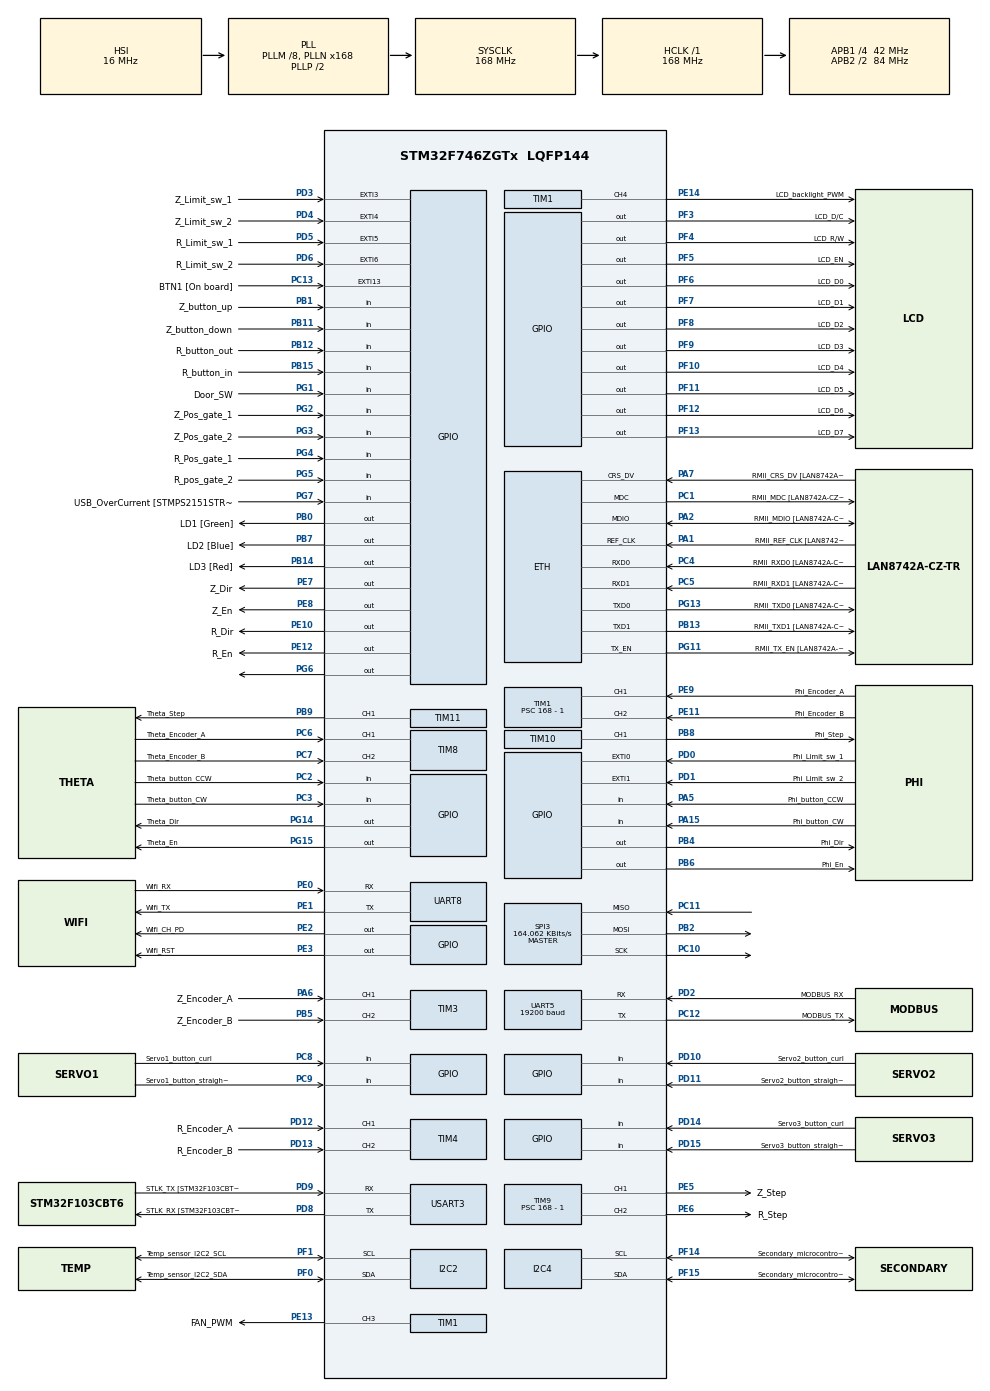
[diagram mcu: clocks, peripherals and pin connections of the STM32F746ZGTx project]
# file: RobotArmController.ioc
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ETH.MediaInterface=HAL_ETH_RMII_MODE
ETH.PHY_Name=LAN8742A_PHY_ADDRESS
ETH.PHY_Value=0
ETH.PhyAddress=0
FREERTOS.INCLUDE_pcTaskGetTaskName=1
FREERTOS.INCLUDE_xEventGroupSetBitFromISR=1
FREERTOS.INCLUDE_xTaskGetCurrentTaskHandle=1
FREERTOS.Tasks01=defaultTask,16,1024,StartDefaultTask,Default,NULL,Static,defaultTaskBuffer,defaultTaskControlBlock
FREERTOS.configCHECK_FOR_STACK_OVERFLOW=2
FREERTOS.configMAX_TASK_NAME_LEN=64
FREERTOS.configTOTAL_HEAP_SIZE=81920
FREERTOS.configUSE_NEWLIB_REENTRANT=1
I2C2.Timing=0x00A0A3F7
I2C4.Timing=0x00A0A3F7
Mcu.Family=STM32F7
Mcu.Name=STM32F746ZGTx
Mcu.Package=LQFP144
NVIC.EXTI0_IRQn=true\:5\:0\:false\:false\:true\:true\:true\:true\:true
NVIC.EXTI15_10_IRQn=true\:5\:0\:false\:false\:true\:true\:true\:true\:true
NVIC.EXTI1_IRQn=true\:5\:0\:false\:false\:true\:false\:true\:true\:true
NVIC.EXTI3_IRQn=true\:5\:0\:false\:false\:true\:false\:true\:true\:true
NVIC.EXTI4_IRQn=true\:5\:0\:false\:false\:true\:false\:true\:true\:true
NVIC.EXTI9_5_IRQn=true\:5\:0\:false\:false\:true\:false\:true\:true\:true
NVIC.PriorityGroup=NVIC_PRIORITYGROUP_4
NVIC.TIM1_BRK_TIM9_IRQn=true\:5\:0\:false\:false\:true\:true\:true\:true\:true
NVIC.TIM1_UP_TIM10_IRQn=true\:5\:0\:false\:false\:true\:true\:true\:true\:true
NVIC.TIM2_IRQn=true\:15\:0\:false\:false\:true\:false\:false\:true\:true
NVIC.TimeBase=TIM2_IRQn
NVIC.TimeBaseIP=TIM2
NVIC.UART8_IRQn=true\:5\:0\:false\:false\:true\:true\:true\:true\:true
PA0/WKUP.GPIO_Label=Servo1_PWM
PA0/WKUP.Signal=S_TIM2_CH1_ETR
PA1.GPIO_Label=RMII_REF_CLK [LAN8742A-CZ-TR_REFCLK0]
PA1.Mode=RMII
PA1.Signal=ETH_REF_CLK
PA10.GPIO_Label=USB_ID
PA10.Signal=USB_OTG_FS_ID
PA11.GPIO_Label=USB_DM
PA11.Signal=USB_OTG_FS_DM
PA12.GPIO_Label=USB_DP
PA12.Signal=USB_OTG_FS_DP
PA13.GPIO_Label=TMS
PA13.Mode=Serial_Wire
PA13.Signal=SYS_JTMS-SWDIO
PA14.GPIO_Label=TCK
PA14.Mode=Serial_Wire
PA14.Signal=SYS_JTCK-SWCLK
PA15.GPIO_Label=Phi_button_CW
PA15.GPIO_PuPd=GPIO_PULLDOWN
PA15.Signal=GPIO_Input
PA2.GPIO_Label=RMII_MDIO [LAN8742A-CZ-TR_MDIO]
PA2.Mode=RMII
PA2.Signal=ETH_MDIO
PA3.GPIO_Label=Servo2_PWM
PA3.Signal=S_TIM2_CH4
PA4.Signal=SPI3_NSS
PA5.GPIO_Label=Phi_button_CCW
PA5.GPIO_PuPd=GPIO_PULLDOWN
PA5.Signal=GPIO_Input
PA6.GPIO_Label=Z_Encoder_A
PA6.Signal=S_TIM3_CH1
PA7.GPIO_Label=RMII_CRS_DV [LAN8742A-CZ-TR_CRS_DV]
PA7.Mode=RMII
PA7.Signal=ETH_CRS_DV
PA8.GPIO_Mode=GPIO_MODE_AF_PP
PA8.GPIO_PuPd=GPIO_NOPULL
PA8.GPIO_Speed=GPIO_SPEED_FREQ_VERY_HIGH
PA8.Signal=USB_OTG_FS_SOF
PA9.GPIO_Mode=GPIO_MODE_INPUT
PA9.GPIO_PuPd=GPIO_NOPULL
PA9.Signal=USB_OTG_FS_VBUS
PB0.GPIO_Label=LD1 [Green]
PB0.Signal=GPIO_Output
PB1.GPIO_Label=Z_button_up
PB1.GPIO_PuPd=GPIO_PULLDOWN
PB1.Signal=GPIO_Input
PB10.GPIO_Label=Servo3_PWM
PB10.Signal=S_TIM2_CH3
PB11.GPIO_Label=Z_button_down
PB11.GPIO_PuPd=GPIO_PULLDOWN
PB11.Signal=GPIO_Input
PB12.GPIO_Label=R_button_out
PB12.GPIO_PuPd=GPIO_PULLDOWN
PB12.Signal=GPIO_Input
PB13.GPIO_Label=RMII_TXD1 [LAN8742A-CZ-TR_TXD1]
PB13.Mode=RMII
PB13.Signal=ETH_TXD1
PB14.GPIO_Label=LD3 [Red]
PB14.Signal=GPIO_Output
PB15.GPIO_Label=R_button_in
PB15.GPIO_PuPd=GPIO_PULLDOWN
PB15.Signal=GPIO_Input
PB2.GPIO_Mode=GPIO_MODE_AF_PP
PB2.Mode=Full_Duplex_Master
PB2.Signal=SPI3_MOSI
PB3.GPIO_Label=SW0
PB3.Signal=SYS_JTDO-SWO
PB4.GPIO_Label=Phi_Dir
PB4.Signal=GPIO_Output
PB5.GPIO_Label=Z_Encoder_B
PB5.Signal=S_TIM3_CH2
PB6.GPIO_Label=Phi_En
PB6.Signal=GPIO_Output
PB7.GPIO_Label=LD2 [Blue]
PB7.Signal=GPIO_Output
PB8.GPIO_Label=Phi_Step
PB8.Signal=S_TIM10_CH1
PB9.GPIO_Label=Theta_Step
PB9.Signal=S_TIM11_CH1
PC1.GPIO_Label=RMII_MDC [LAN8742A-CZ-TR_MDC]
PC1.Mode=RMII
PC1.Signal=ETH_MDC
PC10.Mode=Full_Duplex_Master
PC10.Signal=SPI3_SCK
PC11.Mode=Full_Duplex_Master
PC11.Signal=SPI3_MISO
PC12.GPIO_Label=MODBUS_TX
PC12.Mode=Asynchronous
PC12.Signal=UART5_TX
PC13.GPIO_Label=BTN1 [On board]
PC13.Signal=GPXTI13
PC14/OSC32_IN.Mode=LSE-External-Oscillator
PC14/OSC32_IN.Signal=RCC_OSC32_IN
PC15/OSC32_OUT.Mode=LSE-External-Oscillator
PC15/OSC32_OUT.Signal=RCC_OSC32_OUT
PC2.GPIO_Label=Theta_button_CCW
PC2.GPIO_PuPd=GPIO_PULLUP
PC2.Signal=GPIO_Input
PC3.GPIO_Label=Theta_button_CW
PC3.GPIO_PuPd=GPIO_PULLUP
PC3.Signal=GPIO_Input
PC4.GPIO_Label=RMII_RXD0 [LAN8742A-CZ-TR_RXD0]
PC4.Mode=RMII
PC4.Signal=ETH_RXD0
PC5.GPIO_Label=RMII_RXD1 [LAN8742A-CZ-TR_RXD1]
PC5.Mode=RMII
PC5.Signal=ETH_RXD1
PC6.GPIO_Label=Theta_Encoder_A
PC6.Signal=S_TIM8_CH1
PC7.GPIO_Label=Theta_Encoder_B
PC7.Signal=S_TIM8_CH2
PC8.GPIO_Label=Servo1_button_curl
PC8.GPIO_PuPd=GPIO_PULLUP
PC8.Signal=GPIO_Input
PC9.GPIO_Label=Servo1_button_straighten
PC9.GPIO_PuPd=GPIO_PULLUP
PC9.Signal=GPIO_Input
PD0.GPIO_Label=Phi_Limit_sw_1
PD0.GPIO_ModeDefaultEXTI=GPIO_MODE_IT_RISING_FALLING
PD0.GPIO_PuPd=GPIO_PULLUP
PD0.Signal=GPXTI0
PD1.GPIO_Label=Phi_Limit_sw_2
PD1.GPIO_ModeDefaultEXTI=GPIO_MODE_IT_RISING_FALLING
PD1.GPIO_PuPd=GPIO_PULLUP
PD1.Signal=GPXTI1
PD10.GPIO_Label=Servo2_button_curl
PD10.GPIO_PuPd=GPIO_PULLUP
PD10.Signal=GPIO_Input
PD11.GPIO_Label=Servo2_button_straighten
PD11.GPIO_PuPd=GPIO_PULLUP
PD11.Signal=GPIO_Input
PD12.GPIO_Label=R_Encoder_A
PD12.Signal=S_TIM4_CH1
PD13.GPIO_Label=R_Encoder_B
PD13.Signal=S_TIM4_CH2
PD14.GPIO_Label=Servo3_button_curl
PD14.GPIO_PuPd=GPIO_PULLUP
PD14.Signal=GPIO_Input
PD15.GPIO_Label=Servo3_button_straighten
PD15.GPIO_PuPd=GPIO_PULLUP
PD15.Signal=GPIO_Input
PD2.GPIO_Label=MODBUS_RX
PD2.Mode=Asynchronous
PD2.Signal=UART5_RX
PD3.GPIO_Label=Z_Limit_sw_1
PD3.GPIO_ModeDefaultEXTI=GPIO_MODE_IT_RISING_FALLING
PD3.GPIO_PuPd=GPIO_PULLUP
PD3.Signal=GPXTI3
PD4.GPIO_Label=Z_Limit_sw_2
PD4.GPIO_ModeDefaultEXTI=GPIO_MODE_IT_RISING_FALLING
PD4.GPIO_PuPd=GPIO_PULLUP
PD4.Signal=GPXTI4
PD5.GPIO_Label=R_Limit_sw_1
PD5.GPIO_ModeDefaultEXTI=GPIO_MODE_IT_RISING_FALLING
PD5.GPIO_PuPd=GPIO_PULLUP
PD5.Signal=GPXTI5
PD6.GPIO_Label=R_Limit_sw_2
PD6.GPIO_ModeDefaultEXTI=GPIO_MODE_IT_RISING_FALLING
PD6.GPIO_PuPd=GPIO_PULLUP
PD6.Signal=GPXTI6
PD8.GPIO_Label=STLK_RX [STM32F103CBT6_PA3]
PD8.Mode=Asynchronous
PD8.Signal=USART3_TX
PD9.GPIO_Label=STLK_TX [STM32F103CBT6_PA2]
PD9.Mode=Asynchronous
PD9.Signal=USART3_RX
PE0.GPIO_Label=Wifi_RX
PE0.Mode=Asynchronous
PE0.Signal=UART8_RX
PE1.GPIO_Label=Wifi_TX
PE1.Mode=Asynchronous
PE1.Signal=UART8_TX
PE10.GPIO_Label=R_Dir
PE10.Signal=GPIO_Output
PE11.GPIO_Label=Phi_Encoder_B
PE11.Signal=S_TIM1_CH2
PE12.GPIO_Label=R_En
PE12.Signal=GPIO_Output
PE13.GPIO_Label=FAN_PWM
PE13.Signal=S_TIM1_CH3
PE14.GPIO_Label=LCD_backlight_PWM
PE14.Signal=S_TIM1_CH4
PE2.GPIO_Label=Wifi_CH_PD
PE2.GPIO_Speed=GPIO_SPEED_FREQ_MEDIUM
PE2.Signal=GPIO_Output
PE3.GPIO_Label=Wifi_RST
PE3.Signal=GPIO_Output
PE5.GPIO_Label=Z_Step
PE5.Signal=S_TIM9_CH1
PE6.GPIO_Label=R_Step
PE6.Signal=S_TIM9_CH2
PE7.GPIO_Label=Z_Dir
PE7.Signal=GPIO_Output
PE8.GPIO_Label=Z_En
PE8.Signal=GPIO_Output
PE9.GPIO_Label=Phi_Encoder_A
PE9.Signal=S_TIM1_CH1
PF0.GPIO_Label=Temp_sensor_I2C2_SDA
PF0.Mode=I2C
PF0.Signal=I2C2_SDA
PF1.GPIO_Label=Temp_sensor_I2C2_SCL
PF1.Mode=I2C
PF1.Signal=I2C2_SCL
PF10.GPIO_Label=LCD_D4
PF10.GPIO_Speed=GPIO_SPEED_FREQ_HIGH
PF10.Signal=GPIO_Output
PF11.GPIO_Label=LCD_D5
PF11.GPIO_Speed=GPIO_SPEED_FREQ_HIGH
PF11.Signal=GPIO_Output
PF12.GPIO_Label=LCD_D6
PF12.GPIO_Speed=GPIO_SPEED_FREQ_HIGH
PF12.Signal=GPIO_Output
PF13.GPIO_Label=LCD_D7
PF13.GPIO_Speed=GPIO_SPEED_FREQ_HIGH
PF13.Signal=GPIO_Output
PF14.GPIO_Label=Secondary_microcontroller_I2C4_SCL
PF14.Mode=I2C
PF14.Signal=I2C4_SCL
PF15.GPIO_Label=Secondary_microcontroller_I2C4_SDA
PF15.Mode=I2C
PF15.Signal=I2C4_SDA
PF3.GPIO_Label=LCD_D/C
PF3.GPIO_PuPd=GPIO_NOPULL
PF3.GPIO_Speed=GPIO_SPEED_FREQ_HIGH
PF3.Signal=GPIO_Output
PF4.GPIO_Label=LCD_R/W
PF4.GPIO_Speed=GPIO_SPEED_FREQ_HIGH
PF4.Signal=GPIO_Output
PF5.GPIO_Label=LCD_EN
PF5.GPIO_Speed=GPIO_SPEED_FREQ_LOW
PF5.Signal=GPIO_Output
PF6.GPIO_Label=LCD_D0
PF6.GPIO_Speed=GPIO_SPEED_FREQ_HIGH
PF6.Signal=GPIO_Output
PF7.GPIO_Label=LCD_D1
PF7.GPIO_Speed=GPIO_SPEED_FREQ_HIGH
PF7.Signal=GPIO_Output
PF8.GPIO_Label=LCD_D2
PF8.GPIO_Speed=GPIO_SPEED_FREQ_HIGH
PF8.Signal=GPIO_Output
PF9.GPIO_Label=LCD_D3
PF9.GPIO_Speed=GPIO_SPEED_FREQ_HIGH
PF9.Signal=GPIO_Output
PG1.GPIO_Label=Door_SW
PG1.GPIO_PuPd=GPIO_PULLUP
PG1.Signal=GPIO_Input
PG11.GPIO_Label=RMII_TX_EN [LAN8742A-CZ-TR_TXEN]
PG11.Mode=RMII
PG11.Signal=ETH_TX_EN
PG13.GPIO_Label=RMII_TXD0 [LAN8742A-CZ-TR_TXD0]
PG13.Mode=RMII
PG13.Signal=ETH_TXD0
PG14.GPIO_Label=Theta_Dir
PG14.Signal=GPIO_Output
PG15.GPIO_Label=Theta_En
PG15.Signal=GPIO_Output
PG2.GPIO_Label=Z_Pos_gate_1
PG2.GPIO_PuPd=GPIO_PULLUP
PG2.Signal=GPIO_Input
PG3.GPIO_Label=Z_Pos_gate_2
PG3.GPIO_PuPd=GPIO_PULLUP
PG3.Signal=GPIO_Input
PG4.GPIO_Label=R_Pos_gate_1
PG4.GPIO_PuPd=GPIO_PULLUP
PG4.Signal=GPIO_Input
PG5.GPIO_Label=R_pos_gate_2
PG5.GPIO_PuPd=GPIO_PULLUP
PG5.Signal=GPIO_Input
PG6.Signal=GPIO_Output
PG7.GPIO_Label=USB_OverCurrent [STMPS2151STR_FAULT]
PG7.Signal=GPIO_Input
PH0/OSC_IN.GPIO_Label=MCO [STM32F103CBT6_PA8]
PH0/OSC_IN.Signal=RCC_OSC_IN
PH1/OSC_OUT.Signal=RCC_OSC_OUT
ProjectManager.HeapSize=0x200
ProjectManager.StackSize=0x400
ProjectManager.TargetToolchain=STM32CubeIDE
RCC.48MHZClocksFreq_Value=24000000
RCC.AHBFreq_Value=168000000
RCC.APB1CLKDivider=RCC_HCLK_DIV4
RCC.APB1Freq_Value=42000000
RCC.APB1TimFreq_Value=84000000
RCC.APB2CLKDivider=RCC_HCLK_DIV2
RCC.APB2Freq_Value=84000000
RCC.APB2TimFreq_Value=168000000
RCC.CortexFreq_Value=168000000
RCC.HCLKFreq_Value=168000000
RCC.HSE_VALUE=8000000
RCC.HSI_VALUE=16000000
RCC.PLLM=8
RCC.PLLMUL=RCC_PLL_MUL9
RCC.PLLN=168
RCC.PLLQ=7
RCC.PRESCALERUSB=RCC_USBCLKSOURCE_PLL_DIV1_5
RCC.SYSCLKFreq_VALUE=168000000
RCC.SYSCLKSource=RCC_SYSCLKSOURCE_PLLCLK
RCC.SYSCLKSourceVirtual=RCC_SYSCLKSOURCE_PLLCLK
RCC.USBFreq_Value=48000000
RCC.VCOOutputFreq_Value=336000000
SH.S_TIM10_CH1.0=TIM10_CH1,PWM Generation1 CH1
SH.S_TIM11_CH1.0=TIM11_CH1,PWM Generation1 CH1
SH.S_TIM1_CH1.0=TIM1_CH1,Encoder_Interface
SH.S_TIM1_CH2.0=TIM1_CH2,Encoder_Interface
SH.S_TIM1_CH3.0=TIM1_CH3,PWM Generation3 CH3
SH.S_TIM1_CH4.0=TIM1_CH4,PWM Generation4 CH4
SH.S_TIM2_CH1_ETR.0=TIM2_CH1
SH.S_TIM2_CH3.0=TIM2_CH3
SH.S_TIM2_CH4.0=TIM2_CH4
SH.S_TIM3_CH1.0=TIM3_CH1,Encoder_Interface
SH.S_TIM3_CH2.0=TIM3_CH2,Encoder_Interface
SH.S_TIM4_CH1.0=TIM4_CH1,Encoder_Interface
SH.S_TIM4_CH2.0=TIM4_CH2,Encoder_Interface
SH.S_TIM8_CH1.0=TIM8_CH1,Encoder_Interface
SH.S_TIM8_CH2.0=TIM8_CH2,Encoder_Interface
SH.S_TIM9_CH1.0=TIM9_CH1,PWM Generation1 CH1
SH.S_TIM9_CH2.0=TIM9_CH2,PWM Generation2 CH2
SPI3.BaudRatePrescaler=SPI_BAUDRATEPRESCALER_256
SPI3.CLKPhase=SPI_PHASE_2EDGE
SPI3.CLKPolarity=SPI_POLARITY_HIGH
SPI3.CRCCalculation=SPI_CRCCALCULATION_DISABLE
SPI3.CalculateBaudRate=164.062 KBits/s
SPI3.DataSize=SPI_DATASIZE_8BIT
SPI3.Direction=SPI_DIRECTION_2LINES
SPI3.FirstBit=SPI_FIRSTBIT_LSB
SPI3.Mode=SPI_MODE_MASTER
SPI3.VirtualType=VM_MASTER
TIM1.Channel-PWM\ Generation3\ CH3=TIM_CHANNEL_3
TIM1.Channel-PWM\ Generation4\ CH4=TIM_CHANNEL_4
TIM1.Period=1000 - 1
TIM1.Prescaler=168 - 1
TIM10.Channel=TIM_CHANNEL_1
TIM10.Period=1000 - 1
TIM10.Prescaler=168 - 1
TIM10.Pulse=499
TIM11.Channel=TIM_CHANNEL_1
TIM9.Channel-PWM\ Generation1\ CH1=TIM_CHANNEL_1
TIM9.Channel-PWM\ Generation2\ CH2=TIM_CHANNEL_2
TIM9.Period=1500 - 1
TIM9.Prescaler=168 - 1
TIM9.Pulse-PWM\ Generation1\ CH1=499
TIM9.Pulse-PWM\ Generation2\ CH2=499
UART5.BaudRate=19200
UART5.Parity=PARITY_EVEN
UART8.SwapParam=UART_ADVFEATURE_SWAP_ENABLE
USART3.VirtualMode-Asynchronous=VM_ASYNC
VP_FREERTOS_VS_CMSIS_V2.Mode=CMSIS_V2
VP_SYS_VS_tim2.Mode=TIM2
VP_TIM10_VS_ClockSourceINT.Mode=Enable_Timer
VP_TIM11_VS_ClockSourceINT.Mode=Enable_Timer
VP_TIM9_VS_ClockSourceINT.Mode=Internal
board=NUCLEO-F746ZG

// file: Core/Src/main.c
/* USER CODE BEGIN Header */
/**
  ******************************************************************************
  * @file           : main.c
  * @brief          : Main program body
  ******************************************************************************
  * @attention
  *
  * Copyright (c) 2024 STMicroelectronics.
  * All rights reserved.
  *
  * This software is licensed under terms that can be found in the LICENSE file
  * in the root directory of this software component.
  * If no LICENSE file comes with this software, it is provided AS-IS.
  *
  ******************************************************************************
  */
/* USER CODE END Header */
#include "main.h"
#include "cmsis_os.h"
#include "eth.h"
#include "i2c.h"
#include "spi.h"
#include "tim.h"
#include "usart.h"
#include "gpio.h"

/* USER CODE BEGIN Includes */
#include "cJSON/cJSON.h"

#include "limitswitch.h"
#include "logger.h"
#include "stepper_motor.h"
#include "retarget_io.h"
#include "wifi_module.h"
/* USER CODE END Includes */

void SystemClock_Config(void);
void MX_FREERTOS_Init(void);

int main(void)
{

  /* MCU Configuration--------------------------------------------------------*/

  /* Reset of all peripherals, Initializes the Flash interface and the Systick. */
  HAL_Init();

  /* Configure the system clock */
  SystemClock_Config();

  /* Initialize all configured peripherals */
  MX_GPIO_Init();
  MX_ETH_Init();
  MX_USART3_UART_Init();
  MX_I2C2_Init();
  MX_SPI3_Init();
  MX_TIM1_Init();
  MX_TIM3_Init();
  MX_TIM4_Init();
  MX_TIM8_Init();
  MX_TIM9_Init();
  MX_TIM10_Init();
  MX_TIM11_Init();
  MX_UART5_Init();
  MX_UART8_Init();
  MX_I2C4_Init();
  /* USER CODE BEGIN 2 */
    initLimitswitches();
    initStepperMotors();
    initWifiModule();
    // Set SPI3 NSS signal to idle
    HAL_GPIO_WritePin(GPIOA, GPIO_PIN_4, GPIO_PIN_SET);

    initRetargetIo();
    Logger_Init(200);

    // Use FreeRTOS memory management for cJSON
    cJSON_Hooks hooks;
    hooks.malloc_fn = pvPortMalloc;
    hooks.free_fn = vPortFree;
    cJSON_InitHooks(&hooks);

    HAL_GPIO_WritePin(LD3_GPIO_Port, LD3_Pin, GPIO_PIN_RESET);
  /* USER CODE END 2 */

  /* Init scheduler */
  osKernelInitialize();

  /* Call init function for freertos objects (in cmsis_os2.c) */
  MX_FREERTOS_Init();

  /* Start scheduler */
  osKernelStart();

  /* We should never get here as control is now taken by the scheduler */

  /* Infinite loop */
  while (1)
  {

  }
}

void SystemClock_Config(void)
{
  RCC_OscInitTypeDef RCC_OscInitStruct = {0};
  RCC_ClkInitTypeDef RCC_ClkInitStruct = {0};

  /** Configure LSE Drive Capability
  */
  HAL_PWR_EnableBkUpAccess();

  /** Configure the main internal regulator output voltage
  */
  __HAL_RCC_PWR_CLK_ENABLE();
  __HAL_PWR_VOLTAGESCALING_CONFIG(PWR_REGULATOR_VOLTAGE_SCALE2);

  /** Initializes the RCC Oscillators according to the specified parameters
  * in the RCC_OscInitTypeDef structure.
  */
  RCC_OscInitStruct.OscillatorType = RCC_OSCILLATORTYPE_HSI;
  RCC_OscInitStruct.HSIState = RCC_HSI_ON;
  RCC_OscInitStruct.HSICalibrationValue = RCC_HSICALIBRATION_DEFAULT;
  RCC_OscInitStruct.PLL.PLLState = RCC_PLL_ON;
  RCC_OscInitStruct.PLL.PLLSource = RCC_PLLSOURCE_HSI;
  RCC_OscInitStruct.PLL.PLLM = 8;
  RCC_OscInitStruct.PLL.PLLN = 168;
  RCC_OscInitStruct.PLL.PLLP = RCC_PLLP_DIV2;
  RCC_OscInitStruct.PLL.PLLQ = 7;
  if (HAL_RCC_OscConfig(&RCC_OscInitStruct) != HAL_OK)
  {
    Error_Handler();
  }

  /** Initializes the CPU, AHB and APB buses clocks
  */
  RCC_ClkInitStruct.ClockType = RCC_CLOCKTYPE_HCLK|RCC_CLOCKTYPE_SYSCLK
                              |RCC_CLOCKTYPE_PCLK1|RCC_CLOCKTYPE_PCLK2;
  RCC_ClkInitStruct.SYSCLKSource = RCC_SYSCLKSOURCE_PLLCLK;
  RCC_ClkInitStruct.AHBCLKDivider = RCC_SYSCLK_DIV1;
  RCC_ClkInitStruct.APB1CLKDivider = RCC_HCLK_DIV4;
  RCC_ClkInitStruct.APB2CLKDivider = RCC_HCLK_DIV2;

  if (HAL_RCC_ClockConfig(&RCC_ClkInitStruct, FLASH_LATENCY_5) != HAL_OK)
  {
    Error_Handler();
  }
}

void HAL_TIM_PeriodElapsedCallback(TIM_HandleTypeDef *htim)
{
  if (htim->Instance == TIM2)
  {
    HAL_IncTick();
  }
}

void Error_Handler(void)
{
  /* USER CODE BEGIN Error_Handler_Debug */
  /* User can add his own implementation to report the HAL error return state */
    HAL_GPIO_WritePin(LD3_GPIO_Port, LD3_Pin, GPIO_PIN_SET);
  __disable_irq();
  while (1)
  {
  }
  /* USER CODE END Error_Handler_Debug */
}

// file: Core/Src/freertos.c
/* USER CODE BEGIN Header */
/**
  ******************************************************************************
  * File Name          : freertos.c
  * Description        : Code for freertos applications
  ******************************************************************************
  * @attention
  *
  * Copyright (c) 2024 STMicroelectronics.
  * All rights reserved.
  *
  * This software is licensed under terms that can be found in the LICENSE file
  * in the root directory of this software component.
  * If no LICENSE file comes with this software, it is provided AS-IS.
  *
  ******************************************************************************
  */
/* USER CODE END Header */

#include "FreeRTOS.h"
#include "task.h"
#include "main.h"
#include "cmsis_os.h"

/* USER CODE BEGIN Includes */

#include <stdbool.h>
#include <stdint.h>
#include <stdio.h>
#include <string.h>

#include "event_groups.h"
#include "queue.h"
#include "semphr.h"

#include "limitswitch.h"
#include "logger.h"
#include "mechanical_conf.h"
#include "rtos_priorities.h"
#include "stepper_motor.h"
#include "tim.h"
#include "translation.h" // TODO: Solve naming conflicts.
#include "usart.h"
#include "spi.h"

#include "KAR_MC_handler.h"
#include "WifiController/WifiController.h"
#include "WifiController/SerialHelper.h"

/* USER CODE END Includes */

typedef StaticTask_t osStaticThreadDef_t;
/* USER CODE BEGIN PTD */

typedef int32_t MC_Step_t;

typedef struct PositionCylindrical
{
    MC_Step_t r;
    MC_Step_t phi;
    MC_Step_t z;
} PositionCylindrical_t;

typedef enum AppState
{
    AppState_Error,
    AppState_Idle,
    AppState_DemoMoveControl,
    AppState_GpioControl,
    AppState_WifiControl,
	AppState_ps2Control
} AppState_t;

/* USER CODE END PTD */

/* USER CODE BEGIN PD */

// Task settings
#define INDICATOR_BLINKING_TASK_STACK_SIZE 512
#define INDICATOR_BLINKING_TASK_PRIORITY TASK_PRIORITY_LOWEST
#define WIFI_RECEIVE_TASK_STACK_SIZE 2048
#define WIFI_RECEIVE_TASK_PRIORITY TASK_PRIORITY_ABOVE_NORMAL
#define DEMO_MOVE_CONTROL_TASK_STACK_SIZE 1024
#define DEMO_MOVE_CONTROL_TASK_PRIORITY TASK_PRIORITY_NORMAL
#define GPIO_CONTROL_TASK_STACK_SIZE 1024
#define GPIO_CONTROL_TASK_PRIORITY TASK_PRIORITY_NORMAL
#define PS2_CONTROL_TASK_STACK_SIZE 1024
#define PS2_CONTROL_TASK_PRIORITY TASK_PRIORITY_NORMAL
#define WIFI_CONTROL_TASK_STACK_SIZE 1024
#define WIFI_CONTROL_TASK_PRIORITY TASK_PRIORITY_NORMAL
#define SETUP_TASK_STACK_SIZE 1024
#define SETUP_TASK_PRIORITY TASK_PRIORITY_NORMAL

// Queue settings
#define NEXT_POSITION_QUEUE_LENGTH 64
#define NEXT_POSITION_QUEUE_ITEM_SIZE sizeof(PositionCylindrical_t)

// Event group settings
#define STATE_DEMO_MOVE_CONTROL_BIT (1 << 0)
#define STATE_GPIO_CONTROL_BIT (1 << 1)
#define STATE_WIFI_CONTROL_BIT (1 << 2)
#define STATE_PS2_CONTROL_BIT (1 << 3)

/* USER CODE END PD */

/* USER CODE BEGIN Variables */

// Task variables
static StaticTask_t demoMoveControlTaskBuffer;
static StackType_t demoMoveControlTaskStack[DEMO_MOVE_CONTROL_TASK_STACK_SIZE];
TaskHandle_t demoMoveControlTaskHandle = NULL;
static StaticTask_t gpioControlTaskBuffer;
static StackType_t gpioControlTaskStack[GPIO_CONTROL_TASK_STACK_SIZE];
TaskHandle_t gpioControlTaskHandle = NULL;
static StaticTask_t ps2ControlTaskBuffer;
static StackType_t ps2ControlTaskStack[PS2_CONTROL_TASK_STACK_SIZE];
TaskHandle_t ps2ControlTaskHandle = NULL;
static StaticTask_t indicatorBlinkingTaskBuffer;
static StackType_t indicatorBlinkingTaskStack[INDICATOR_BLINKING_TASK_STACK_SIZE];
TaskHandle_t indicatorBlinkingTaskHandle = NULL;
TaskHandle_t setupTaskHandle = NULL;
static StaticTask_t wifiControlTaskBuffer;
static StackType_t wifiControlTaskStack[WIFI_CONTROL_TASK_STACK_SIZE];
TaskHandle_t wifiControlTaskHandle = NULL;
static StaticTask_t wifiReceiveTaskBuffer;
static StackType_t wifiReceiveTaskStack[WIFI_RECEIVE_TASK_STACK_SIZE];
TaskHandle_t wifiReceiveTaskHandle = NULL;

// Semaphores and mutexes
StaticSemaphore_t controlMutexBuffer;
SemaphoreHandle_t controlMutexHandle = NULL;
StaticSemaphore_t wifiReceiveStartedFlagBuffer;
SemaphoreHandle_t wifiReceiveStartedFlagHandle = NULL;

// Queue variables
static StaticQueue_t nextPositionQueueBuffer;
static uint8_t nextPositionQueueStorageArea[NEXT_POSITION_QUEUE_LENGTH * NEXT_POSITION_QUEUE_ITEM_SIZE];
QueueHandle_t nextPositionQueueHandle = NULL;

// Event group variables
static StaticEventGroup_t stateEventGroupBuffer;
EventGroupHandle_t stateEventGroupHandle = NULL;

// Other variables
volatile AppState_t appState = AppState_Idle;

/* USER CODE END Variables */
/* Definitions for defaultTask */
osThreadId_t defaultTaskHandle;
uint32_t defaultTaskBuffer[ 1024 ];
osStaticThreadDef_t defaultTaskControlBlock;
const osThreadAttr_t defaultTask_attributes = {
  .name = "defaultTask",
  .cb_mem = &defaultTaskControlBlock,
  .cb_size = sizeof(defaultTaskControlBlock),
  .stack_mem = &defaultTaskBuffer[0],
  .stack_size = sizeof(defaultTaskBuffer),
  .priority = (osPriority_t) osPriorityBelowNormal,
};

/* USER CODE BEGIN FunctionPrototypes */

// Task functions
void demoMoveControlTask(void *pvParameters);
void gpioControlTask(void *pvParameters);
void ps2ControlTask(void *pvParameters);
void indicatorBlinkingTask(void *pvParameters);
void setupTask(void *pvParameters);
void wifiControlTask(void *pvParameters);
void wifiReceiveTask(void *pvParameters);

static void changeAppStateFromISR(BaseType_t *xHigherPriorityTaskWoken);
static bool debounce(uint32_t *last_tick, uint32_t tick_count);
static void handleButtonAction(const char *args);
static void homingSequence();
static void moveToPosition(const PositionCylindrical_t *position);
static void sendNewPosition(const char *btn);
static void setupWifi();

/* USER CODE END FunctionPrototypes */

void StartDefaultTask(void *argument);

void MX_FREERTOS_Init(void); /* (MISRA C 2004 rule 8.1) */

/* Hook prototypes */
void vApplicationStackOverflowHook(xTaskHandle xTask, signed char *pcTaskName);

/* USER CODE BEGIN 4 */
void vApplicationStackOverflowHook(xTaskHandle xTask, signed char *pcTaskName)
{
   /* Run time stack overflow checking is performed if
   configCHECK_FOR_STACK_OVERFLOW is defined to 1 or 2. This hook function is
   called if a stack overflow is detected. */
    printf("Stack Overflow: %s\n", pcTaskName);
    while (1)
    {
    }
}
/* USER CODE END 4 */

void MX_FREERTOS_Init(void) {

  /* USER CODE BEGIN RTOS_MUTEX */
    controlMutexHandle = xSemaphoreCreateMutexStatic(&controlMutexBuffer);
    wifiReceiveStartedFlagHandle = xSemaphoreCreateBinaryStatic(&wifiReceiveStartedFlagBuffer);
  /* USER CODE END RTOS_MUTEX */

  /* USER CODE BEGIN RTOS_QUEUES */
    nextPositionQueueHandle = xQueueCreateStatic(
        NEXT_POSITION_QUEUE_LENGTH,
        NEXT_POSITION_QUEUE_ITEM_SIZE,
        nextPositionQueueStorageArea,
        &nextPositionQueueBuffer);
    configASSERT(nextPositionQueueHandle != NULL);
  /* USER CODE END RTOS_QUEUES */

  /* Create the thread(s) */
  /* creation of defaultTask */
  defaultTaskHandle = osThreadNew(StartDefaultTask, NULL, &defaultTask_attributes);

  /* USER CODE BEGIN RTOS_THREADS */
    indicatorBlinkingTaskHandle = xTaskCreateStatic(
          indicatorBlinkingTask,
          "IndicatorBlinking",
          INDICATOR_BLINKING_TASK_STACK_SIZE,
          NULL,
          INDICATOR_BLINKING_TASK_PRIORITY,
          indicatorBlinkingTaskStack,
          &indicatorBlinkingTaskBuffer);
    configASSERT(indicatorBlinkingTaskHandle != NULL);

    wifiReceiveTaskHandle = xTaskCreateStatic(
          wifiReceiveTask,
          "WifiReceive",
          WIFI_RECEIVE_TASK_STACK_SIZE,
          NULL,
          WIFI_RECEIVE_TASK_PRIORITY,
          wifiReceiveTaskStack,
          &wifiReceiveTaskBuffer);
    configASSERT(wifiReceiveTaskHandle != NULL);

    demoMoveControlTaskHandle = xTaskCreateStatic(
          demoMoveControlTask,
          "DemoMoveControl",
          DEMO_MOVE_CONTROL_TASK_STACK_SIZE,
          NULL,
          DEMO_MOVE_CONTROL_TASK_PRIORITY,
          demoMoveControlTaskStack,
          &demoMoveControlTaskBuffer);
    configASSERT(demoMoveControlTaskHandle != NULL);

    gpioControlTaskHandle = xTaskCreateStatic(
          gpioControlTask,
          "GpioControl",
          GPIO_CONTROL_TASK_STACK_SIZE,
          NULL,
          GPIO_CONTROL_TASK_PRIORITY,
          gpioControlTaskStack,
          &gpioControlTaskBuffer);
    configASSERT(gpioControlTaskHandle != NULL);

    ps2ControlTaskHandle = xTaskCreateStatic(
          ps2ControlTask,
          "ps2Control",
          PS2_CONTROL_TASK_STACK_SIZE,
          NULL,
          PS2_CONTROL_TASK_PRIORITY,
          ps2ControlTaskStack,
          &ps2ControlTaskBuffer);
    configASSERT(ps2ControlTaskHandle != NULL);

    wifiControlTaskHandle = xTaskCreateStatic(
          wifiControlTask,
          "WifiControl",
          WIFI_CONTROL_TASK_STACK_SIZE,
          NULL,
          WIFI_CONTROL_TASK_PRIORITY,
          wifiControlTaskStack,
          &wifiControlTaskBuffer);
    configASSERT(wifiControlTaskHandle != NULL);

    configASSERT(xTaskCreate(
          setupTask,
          "Setup",
          SETUP_TASK_STACK_SIZE,
          NULL,
          SETUP_TASK_PRIORITY,
          &setupTaskHandle) == pdPASS);
  /* USER CODE END RTOS_THREADS */

  /* USER CODE BEGIN RTOS_EVENTS */
    stateEventGroupHandle = xEventGroupCreateStatic(&stateEventGroupBuffer);
    configASSERT(stateEventGroupHandle != NULL);
  /* USER CODE END RTOS_EVENTS */

}

void StartDefaultTask(void *argument)
{
  /* USER CODE BEGIN StartDefaultTask */
    while (1)
    {
        PositionCylindrical_t cp = { -1, -1, -1 };
        vPortEnterCritical();
        cp.r = stepper_motors[MC_MOTORID_R].currPos;
        cp.phi = stepper_motors[MC_MOTORID_PHI].currPos;
        cp.z = stepper_motors[MC_MOTORID_Z].currPos;
        vPortExitCritical();
        logInfo(
            "position: (%ld, %ld, %ld), state: %d",
            cp.r, cp.phi, cp.z,
            appState);

        size_t free_heap_size = xPortGetFreeHeapSize();
        size_t minimum_free_heap_size = xPortGetMinimumEverFreeHeapSize();
        logInfo(
            "heap\n"
            "\t- free heap: %ul / %ul (%d %%)\n"
            "\t- minimum free heap: %ul / %ul (%d %%)",
            free_heap_size,
            configTOTAL_HEAP_SIZE,
            100 * free_heap_size / configTOTAL_HEAP_SIZE,
            minimum_free_heap_size,
            configTOTAL_HEAP_SIZE,
            100 * minimum_free_heap_size / configTOTAL_HEAP_SIZE);

        vTaskDelay(pdMS_TO_TICKS(3000));
    }
  /* USER CODE END StartDefaultTask */
}

/* USER CODE BEGIN Application */

/*
 *===================================================================*
 * Function name: homing_sequence
 *-------------------------------------------------------------------
 * Description:
 * This function is responsible the to do the first homing sequence. It drives all the motors towards negative direction
 * to the point where all of the axis are at the zero position. Here the current position values get the zero initial value.
 * After the sequence the timer interrupts can follow the movement of the arm.
 * After power reset homing must run again.
 *-------------------------------------------------------------------
 */
static void homingSequence()
{
    e_MC_ErrorCode_t ec = u8_MC_StartAllMotor_f(stepper_motors, MC_DIR_NEGATIVE);

    if (ec == e_MC_ErrorCode_OK)
    {
        bool r_finished = false, phi_finished = false, z_finished = false;

        // Waiting until all of the motors have reached their limit
        while (!(r_finished && phi_finished && z_finished))
        {
            // R axis check
            if ((!r_finished) && limit_switches[MC_MOTORID_R].null_point)
            {
                v_MC_StopMotor_f(stepper_motors, MC_MOTORID_R);
                stepper_motors[MC_MOTORID_R].currPos = 0;
                r_finished = true;
            }

            // Phi axis check
            if ((!phi_finished) && limit_switches[MC_MOTORID_PHI].null_point)
            {
                v_MC_StopMotor_f(stepper_motors, MC_MOTORID_PHI);
                stepper_motors[MC_MOTORID_PHI].currPos = 0;
                phi_finished = true;
            }

            // Z axis check
            if ((!z_finished) && limit_switches[MC_MOTORID_Z].null_point)
            {
                v_MC_StopMotor_f(stepper_motors, MC_MOTORID_Z);
                stepper_motors[MC_MOTORID_Z].currPos = 0;
                z_finished = true;
            }

            vTaskDelay(10);
        }

        logInfo("Homing complete.");
    }
    else
    {
        logError("Homig error!");
        Error_Handler();
    }
}

static void changeAppStateFromISR(BaseType_t *pxHigherPriorityTaskWoken)
{
    // Change the app state and wake up the appropriate task.
    switch (appState)
    {
    case AppState_Idle:
        appState = AppState_DemoMoveControl;
        xEventGroupSetBitsFromISR(
                stateEventGroupHandle,
                STATE_DEMO_MOVE_CONTROL_BIT,
                pxHigherPriorityTaskWoken);
        break;
    case AppState_DemoMoveControl:
        appState = AppState_GpioControl;
        xEventGroupSetBitsFromISR(
                stateEventGroupHandle,
                STATE_GPIO_CONTROL_BIT,
                pxHigherPriorityTaskWoken);
        break;
    case AppState_GpioControl:
        appState = AppState_WifiControl;
        xEventGroupSetBitsFromISR(
                stateEventGroupHandle,
                STATE_WIFI_CONTROL_BIT,
                pxHigherPriorityTaskWoken);
        break;
    case AppState_WifiControl:
        appState = AppState_ps2Control;
        xEventGroupSetBitsFromISR(
                stateEventGroupHandle,
                STATE_PS2_CONTROL_BIT,
                pxHigherPriorityTaskWoken);
        break;
    case AppState_ps2Control:
        appState = AppState_DemoMoveControl;
        xEventGroupSetBitsFromISR(
                stateEventGroupHandle,
                STATE_DEMO_MOVE_CONTROL_BIT,
                pxHigherPriorityTaskWoken);
        break;
    default:
        appState = AppState_Error;
        break;
    }
}

static bool debounce(uint32_t *last_tick, uint32_t tick_count)
{
    uint32_t current_tick = HAL_GetTick();
    if (current_tick - *last_tick > tick_count)
    {
        *last_tick = current_tick;
        return true;
    }
    return false;
}

static inline bool check_move_finished(const s_MC_StepperMotor *sm, const s_GEO_LimitSwitch *ls)
{
    // {next position reached} || {limit max reached} || {limit min reached}
    return ((sm->dir == MC_DIR_POSITIVE) ? (sm->currPos >= sm->nextPos) : (sm->currPos <= sm->nextPos))
            || (ls->max_point && (sm->dir == MC_DIR_POSITIVE))
            || (ls->null_point && (sm->dir == MC_DIR_NEGATIVE));
}

static void moveToPosition(const PositionCylindrical_t *position)
{
    vPortEnterCritical();
    stepper_motors[MC_MOTORID_R].nextPos = position->r;
    stepper_motors[MC_MOTORID_PHI].nextPos = position->phi;
    stepper_motors[MC_MOTORID_Z].nextPos = position->z;
    vPortExitCritical();

    u8_MC_setAllMotorDir_TowardsDesiredPos_f(stepper_motors);

    u8_MC_StartMotor_f(stepper_motors, MC_MOTORID_R, stepper_motors[MC_MOTORID_R].dir);
    u8_MC_StartMotor_f(stepper_motors, MC_MOTORID_PHI, stepper_motors[MC_MOTORID_PHI].dir);
    u8_MC_StartMotor_f(stepper_motors, MC_MOTORID_Z, stepper_motors[MC_MOTORID_Z].dir);

    bool r_finished = false;
    bool phi_finished = false;
    bool z_finished = false;

    /* Wait for tool to reach next position */
    while (!(r_finished && phi_finished && z_finished))
    {
        if ((!r_finished) && check_move_finished(&(stepper_motors[MC_MOTORID_R]), &(limit_switches[MC_MOTORID_R])))
        {
            v_MC_StopMotor_f(stepper_motors, MC_MOTORID_R);
            r_finished = true;
        }

        if ((!phi_finished) && check_move_finished(&(stepper_motors[MC_MOTORID_PHI]), &(limit_switches[MC_MOTORID_PHI])))
        {
            v_MC_StopMotor_f(stepper_motors, MC_MOTORID_PHI);
            phi_finished = true;
        }

        if ((!z_finished) && check_move_finished(&(stepper_motors[MC_MOTORID_Z]), &(limit_switches[MC_MOTORID_Z])))
        {
            v_MC_StopMotor_f(stepper_motors, MC_MOTORID_Z);
            z_finished = true;
        }

        vTaskDelay(pdMS_TO_TICKS(10));
    }
}

static void sendNewPosition(const char *btn)
{
    PositionCylindrical_t position;
    // Disable OS and interrupts while creating local copy of global data.
    vPortEnterCritical();
    position.r = stepper_motors[MC_MOTORID_R].currPos;
    position.phi = stepper_motors[MC_MOTORID_PHI].currPos;
    position.z = stepper_motors[MC_MOTORID_Z].currPos;
    vPortExitCritical();

    // The press of a button moves the robot 1/20 of the full range along the specific axis.
    const MC_Step_t inc_r = MC_MAXPOS_R / 20;
    const MC_Step_t inc_phi = MC_MAXPOS_PHI / 20;
    const MC_Step_t inc_z = MC_MAXPOS_Z / 20;

    if (strncmp(btn, "rp", 2) == 0)
    {
        position.r += inc_r;
        if (position.r > MC_MAXPOS_R)
        {
            position.r = MC_MAXPOS_R;
        }
    }
    else if (strncmp(btn, "rm", 2) == 0)
    {
        position.r -= inc_r;
        if (position.r < 0)
        {
            position.r = 0;
        }
    }
    else if (strncmp(btn, "fp", 2) == 0)
    {
        position.phi += inc_phi;
        if (position.phi > MC_MAXPOS_PHI)
        {
            position.phi = MC_MAXPOS_PHI;
        }
    }
    else if (strncmp(btn, "fm", 2) == 0)
    {
        position.phi -= inc_phi;
        if (position.phi < 0)
        {
            position.phi = 0;
        }
    }
    else if (strncmp(btn, "zp", 2) == 0)
    {
        position.z += inc_z;
        if (position.z > MC_MAXPOS_Z)
        {
            position.z = MC_MAXPOS_Z;
        }
    }
    else if (strncmp(btn, "zm", 2) == 0)
    {
        position.z -= inc_z;
        if (position.z < 0)
        {
            position.z = 0;
        }
    }
    else if (strncmp(btn, "hx", 2) == 0)
    {
        position.r = 0;
        position.phi = 0;
        position.z = 0;
    }

    xQueueSend(nextPositionQueueHandle, &position, 10);
}

static void handleButtonAction(const char *args)
{
    // Use the default GUI of the Wi-Fi controller which provides simple buttons for moving the
    // motors of the robotarm.
    char btn[3] = { '\0' };

    const char *arg_text = "btn=";
    const size_t arg_text_length = 4;

    char *p = strstr(args, arg_text);
    if ((p != NULL) && (strlen(p) >= (arg_text_length + 2)))
    {
        strncpy(btn, p + arg_text_length, 2);
        sendNewPosition(btn);
    }
    else
    {
        strcpy(btn, "xx");
    }

    logInfo("Button action: %s", btn);
}

const char *find_param_value(const char *message, const char *param_name)
{
    // TODO: This is just an arbitrary number. Further investigation needed!
    #define MAX_PARAM_NAME_LENGTH 32

    char pattern[MAX_PARAM_NAME_LENGTH + 2] = {'\0'};
    snprintf(pattern, MAX_PARAM_NAME_LENGTH + 2, "%s=", param_name);
    char *start = strstr(message, pattern);
    if (!start)
    {
        return NULL;
    }
    return start + strlen(pattern);
}

static void handleCoordCylAction(const char *args)
{
    const char *param_r = "r";
    const char *param_phi = "phi";
    const char *param_z = "z";

    PositionCylindrical_t position;
    const char *param_value_ptr = NULL;
    int param_value = 0;

    param_value_ptr = find_param_value(args, param_r);
    if (param_value_ptr != NULL)
    {
        sscanf(param_value_ptr, "%d", &param_value);
        position.r = (param_value <= 0) ? 0 : (param_value > MOTOR_TOTAL_STEP_R) ? MOTOR_TOTAL_STEP_R : param_value;
    }
    else
    {
        position.r = param_value = 0;
    }

    param_value_ptr = find_param_value(args, param_phi);
    if (param_value_ptr != NULL)
    {
        sscanf(param_value_ptr, "%d", &param_value);
        position.phi = (param_value <= 0) ? 0 : (param_value > MOTOR_TOTAL_STEP_PHI) ? MOTOR_TOTAL_STEP_PHI : param_value;
    }
    else
    {
        position.phi = param_value = 0;
    }

    param_value_ptr = find_param_value(args, param_z);
    if (param_value_ptr != NULL)
    {
        sscanf(param_value_ptr, "%d", &param_value);
        position.z = (param_value <= 0) ? 0 : (param_value > MOTOR_TOTAL_STEP_Z) ? MOTOR_TOTAL_STEP_Z : param_value;
    }
    else
    {
        position.z = param_value = 0;
    }

    logInfo("Leap: (%ld, %ld, %ld)", position.r, position.phi, position.z);

    xQueueSend(nextPositionQueueHandle, &position, 10);
}

static void setupWifi()
{
    const char *ap_ssid = "indactrobot";
    const char *ap_password = "pirosalma";

    WifiController_ActionList_t *action_list = WifiController_WifiController_GetActionList();
    WifiController_ActionList_Add(action_list, "/button", handleButtonAction);
    WifiController_ActionList_Add(action_list, "/coord/cyl", handleCoordCylAction);

    int count = 0;
    while ((uxSemaphoreGetCount(wifiReceiveStartedFlagHandle) == 0)
            && (count < 100))
    {
        count++;
        vTaskDelay(10);
    }
    if (uxSemaphoreGetCount(wifiReceiveStartedFlagHandle) == 0)
    {
        logError("WifiReceive task was not started.");
        return;
    }

    // Wait for the module to start after power-up
    vTaskDelay(pdMS_TO_TICKS(1000));

    if (WifiController_WifiController_ResetModule() != WC_ErrorCode_NONE)
    {
        logError("Wi-Fi reset error.");
        return;
    }

    // Wait for the module to reset
    vTaskDelay(pdMS_TO_TICKS(1000));

    if (WifiController_WifiController_SetSsid(ap_ssid) != WC_ErrorCode_NONE)
    {
        logError("Wi-Fi set SSID error.");
        return;
    }

    if (WifiController_WifiController_SetPassword(ap_password) != WC_ErrorCode_NONE)
    {
        logError("Wi-Fi set password error.");
        return;
    }

    if (WifiController_WifiController_BeginAccessPoint(10000) != WC_ErrorCode_NONE)
    {
        logError("Wi-Fi begin access point error.");
        return;
    }
}

void setupTask(void *pvParameters)
{
    // ================================================================================
    // Wi-Fi settings
    // ================================================================================
    setupWifi();

    // ================================================================================
    // Homing, then release control
    // ================================================================================
    homingSequence();
    xSemaphoreGive(controlMutexHandle);

    // ================================================================================
    // Start application
    // ================================================================================
    appState = AppState_DemoMoveControl;
    xEventGroupSetBits(stateEventGroupHandle, STATE_DEMO_MOVE_CONTROL_BIT);

    vTaskDelete(NULL);
}

/*
 *===================================================================*
 * Function name: indicatorBlinkingTask
 *-------------------------------------------------------------------
 * Description:
 * Using LEDs to indicate any software error on the board.
 *-------------------------------------------------------------------
 */
void indicatorBlinkingTask(void *pvParameters)
{
    while (1)
    {
        if (appState == AppState_Error)
        {
            HAL_GPIO_WritePin(RedLed_LD3_GPIO_Port, RedLed_LD3_Pin, GPIO_PIN_SET);
            vTaskDelay(pdMS_TO_TICKS(200));
            HAL_GPIO_WritePin(RedLed_LD3_GPIO_Port, RedLed_LD3_Pin, GPIO_PIN_RESET);
            vTaskDelay(pdMS_TO_TICKS(200));
        }
        else
        {
            HAL_GPIO_WritePin(GreenLed_LD1_GPIO_Port, GreenLed_LD1_Pin, GPIO_PIN_SET);
            vTaskDelay(pdMS_TO_TICKS(500));
            HAL_GPIO_WritePin(GreenLed_LD1_GPIO_Port, GreenLed_LD1_Pin, GPIO_PIN_RESET);
            vTaskDelay(pdMS_TO_TICKS(500));
        }
    }
}

void wifiReceiveTask(void *pvParameters)
{
    xSemaphoreGive(wifiReceiveStartedFlagHandle);

    while (1)
    {
        WifiController_WifiController_Receive();
    }
}

/*
 *===================================================================*
 * Function name: demoMoveControlTask
 *-------------------------------------------------------------------
 * Description:
 * Purpose of this task is to show off, to show the kids how cool this huge pile of metal and cable is.
 * It doesn't do much: There is 5 positions declared and stored in a queue. The task takes the positions
 * and drives the arm to them in an infinite loop.
 *-------------------------------------------------------------------
 */
void demoMoveControlTask(void *pvParameters)
{
    // Demo positions
    PositionCylindrical_t positions[5];
    positions[0].r = 0;
    positions[0].phi = 0;
    positions[0].z = 0;
    positions[1].r = 400;
    positions[1].phi = 4000;
    positions[1].z = 4000;
    positions[2].r = 0;
    positions[2].phi = 9000;
    positions[2].z = 7000;
    positions[3].r = 900;
    positions[3].phi = 13874;
    positions[3].z = 10000;
    positions[4].r = 200;
    positions[4].phi = 6000;
    positions[4].z = 5000;

    // Only enter the loop if the control is not taken by any of the other tasks
    xSemaphoreTake(controlMutexHandle, portMAX_DELAY);
    logInfo("Take control.");

    size_t idx = 0;
    while (1)
    {
        if (appState != AppState_DemoMoveControl)
        {
            // Give up the control
            xSemaphoreGive(controlMutexHandle);
            logInfo("Give control.");

            // Wait for the task specific wake-up event
            xEventGroupWaitBits(
                    stateEventGroupHandle,
                    STATE_DEMO_MOVE_CONTROL_BIT,
                    pdTRUE,
                    pdTRUE,
                    portMAX_DELAY);
            logInfo("Wake-up.");

            // Wait for the other tasks to give up control and take it
            xSemaphoreTake(controlMutexHandle, portMAX_DELAY);
            logInfo("Take control.");

            // Always start from the first position
            idx = 0;
        }

        moveToPosition(&positions[idx]);
        idx = (idx + 1) % 5;
        vTaskDelay(pdMS_TO_TICKS(1000));
    }
}

/*
 *===================================================================*
 * Function name: gpioControlTask
 *-------------------------------------------------------------------
 * Description:
 * This task lets the user to control the arm via GPIO buttons
 *-------------------------------------------------------------------
 */
void gpioControlTask(void *pvParameters)
{
    s_GEN_GPIO r_pos_button = {
            .GPIO_Port = motor_r_positive_button_GPIO_Port,
            .GPIO_Pin = motor_r_positive_button_Pin
    };
    s_GEN_GPIO r_neg_button = {
            .GPIO_Port = motor_r_negative_button_GPIO_Port,
            .GPIO_Pin = motor_r_negative_button_Pin
    };
    s_GEN_GPIO fi_pos_button = {
            .GPIO_Port = motor_fi_positive_button_GPIO_Port,
            .GPIO_Pin = motor_fi_positive_button_Pin
    };
    s_GEN_GPIO fi_neg_button = {
            .GPIO_Port = motor_fi_negative_button_GPIO_Port,
            .GPIO_Pin = motor_fi_negative_button_Pin
    };
    s_GEN_GPIO z_pos_button = {
            .GPIO_Port = motor_z_positive_button_GPIO_Port,
            .GPIO_Pin = motor_z_positive_button_Pin
    };
    s_GEN_GPIO z_neg_button = {
            .GPIO_Port = motor_z_negative_button_GPIO_Port,
            .GPIO_Pin = motor_z_negative_button_Pin
    };

    // Only enter the loop if the control is not taken by any of the other tasks
    xSemaphoreTake(controlMutexHandle, portMAX_DELAY);
    logInfo("Take control.");

    while (1)
    {
        if (appState != AppState_GpioControl)
        {
            // Give up the control
            xSemaphoreGive(controlMutexHandle);
            logInfo("Give control.");

            // Wait for the task specific wake-up event
            xEventGroupWaitBits(
                    stateEventGroupHandle,
                    STATE_GPIO_CONTROL_BIT,
                    pdTRUE,
                    pdTRUE,
                    portMAX_DELAY);
            logInfo("Wake-up.");

            // Wait for the other tasks to give up control and take it
            xSemaphoreTake(controlMutexHandle, portMAX_DELAY);
            logInfo("Take control.");
        }

        /* Axis control functions */
        u8_MC_ControlMotor_viaGPIO_f(stepper_motors, MC_MOTORID_R, limit_switches, r_pos_button, r_neg_button);
        u8_MC_ControlMotor_viaGPIO_f(stepper_motors, MC_MOTORID_PHI, limit_switches, fi_pos_button, fi_neg_button);
        u8_MC_ControlMotor_viaGPIO_f(stepper_motors, MC_MOTORID_Z, limit_switches, z_pos_button, z_neg_button);

        vTaskDelay(50);
    }
}

/*
 *===================================================================*
 * Function name: ps2ControlTask
 *-------------------------------------------------------------------
 * Description:
 * This task lets the user to control the arm via PS2 controller
 *-------------------------------------------------------------------
 */
void ps2ControlTask(void *pvParameters)
{
    u_MC_PS2response resp;
    uint8_t pTxData[5] = {0x01, 0x42, 0, 0xff, 0xff};
    uint8_t pRxData[8] = {0};

    // Only enter the loop if the control is not taken by any of the other tasks
    xSemaphoreTake(controlMutexHandle, portMAX_DELAY);
    logInfo("Take control.");

    while (1)
    {
        if (appState != AppState_ps2Control)
        {
            // Give up the control
            xSemaphoreGive(controlMutexHandle);
            logInfo("Give control.");

            // Wait for the task specific wake-up event
            xEventGroupWaitBits(
                    stateEventGroupHandle,
                    STATE_PS2_CONTROL_BIT,
                    pdTRUE,
                    pdTRUE,
                    portMAX_DELAY);
            logInfo("Wake-up.");

            // Wait for the other tasks to give up control and take it
            xSemaphoreTake(controlMutexHandle, portMAX_DELAY);
            logInfo("Take control.");
        }

        HAL_GPIO_WritePin(GPIOA, GPIO_PIN_4, GPIO_PIN_RESET);
        HAL_StatusTypeDef spi_status = HAL_SPI_TransmitReceive(&hspi3, pTxData, pRxData, MC_SPI_RXBUFFER_LENGTH, 10);
        HAL_GPIO_WritePin(GPIOA, GPIO_PIN_4, GPIO_PIN_SET);

        switch (spi_status)
        {
        case HAL_OK:
            // SPI is configured for LSB
            resp.U = ((uint16_t)pRxData[4] << 8u) | (uint16_t)pRxData[3];
            break;
        case HAL_TIMEOUT:
            // The controller is not responding, set everything to zero to stop motors
            resp.U = 0;
            break;
        default:
            // There was an unexpected error in the SPI communication, set everything to zero to stop motors
            resp.U = 0;
            u8_MC_HandlePS2Dir_f(stepper_motors, MC_MOTORID_R, limit_switches, resp.B.o, resp.B.x);
            u8_MC_HandlePS2Dir_f(stepper_motors, MC_MOTORID_PHI, limit_switches, resp.B.left, resp.B.right);
            u8_MC_HandlePS2Dir_f(stepper_motors, MC_MOTORID_Z, limit_switches, resp.B.up, resp.B.down);
            logError("SPI error!");
            vTaskDelay(pdMS_TO_TICKS(2000));
            continue;
        }

        u8_MC_HandlePS2Dir_f(stepper_motors, MC_MOTORID_R, limit_switches, resp.B.o, resp.B.x);
        u8_MC_HandlePS2Dir_f(stepper_motors, MC_MOTORID_PHI, limit_switches, resp.B.left, resp.B.right);
        u8_MC_HandlePS2Dir_f(stepper_motors, MC_MOTORID_Z, limit_switches, resp.B.up, resp.B.down);

        vTaskDelay(pdMS_TO_TICKS(20));
    }
}

void wifiControlTask(void *pvParameters)
{
    // Only enter the loop if the control is not taken by any of the other tasks
    xSemaphoreTake(controlMutexHandle, portMAX_DELAY);
    logInfo("Take control.");

    while (1)
    {
        if (appState != AppState_WifiControl)
        {
            // Give up the control
            xSemaphoreGive(controlMutexHandle);
            logInfo("Give control.");

            // Wait for the task specific wake-up event
            xEventGroupWaitBits(
                    stateEventGroupHandle,
                    STATE_WIFI_CONTROL_BIT,
                    pdTRUE,
                    pdTRUE,
                    portMAX_DELAY);
            logInfo("Wake-up.");

            // Wait for the other tasks to give up control and take it
            xSemaphoreTake(controlMutexHandle, portMAX_DELAY);
            logInfo("Take control.");

            // Empty the queue before continuing
            xQueueReset(nextPositionQueueHandle);
        }

        PositionCylindrical_t position;
        if (xQueueReceive(nextPositionQueueHandle, &position, 200) == pdTRUE)
        {
            logInfo("Position received: (%ld, %ld, %ld).", position.r, position.phi, position.z);
            moveToPosition(&position);
        }
    }
}

/*
 *===================================================================*
 * Function name: HAL_GPIO_EXTI_Callback
 *-------------------------------------------------------------------
 * Description:
 * When the arm reaches it's limits, the limit switches trigger external interrupt request.
 * To prevent further movement, the motor of the axis stops and starting the motor to that direction gets forbidden temporarily.
 * The mode changing button also uses EXTI. In this case the s_program_status.task_id is updated.
 *
 * INPUT:
 * @param (uint16_t) GPIO_Pin: GPIO Pin number which had triggered the interrupt.
 *
 * OUTPUT: none
 *-------------------------------------------------------------------
 */
void HAL_GPIO_EXTI_Callback(uint16_t GPIO_Pin)
{
    BaseType_t xHigherPriorityTaskWoken = pdFALSE;
    static uint32_t last_tick = 0u;

    switch (GPIO_Pin)
    {
    case controller_mode_switch_Pin:
        if (debounce(&last_tick, 500))
        {
            changeAppStateFromISR(&xHigherPriorityTaskWoken);
        }
        break;
    case lsw_r_null_Pin:
        limit_switches[MC_MOTORID_R].null_point = HAL_GPIO_ReadPin(lsw_r_null_GPIO_Port, lsw_r_null_Pin) == LSW_R_NULL_ACTIVE;
        if (limit_switches[MC_MOTORID_R].null_point)
        {
            stepper_motors[MC_MOTORID_R].currPos = 0;
            stepper_motors[MC_MOTORID_R].allowedDir = MC_ALLOWDIR_POSDIR;
        }
        else
        {
            stepper_motors[MC_MOTORID_R].allowedDir = MC_ALLOWDIR_BOTHDIR;
        }
        break;
    case lsw_r_max_Pin:
        limit_switches[MC_MOTORID_R].max_point = HAL_GPIO_ReadPin(lsw_r_max_GPIO_Port, lsw_r_max_Pin) == LSW_R_MAX_ACTIVE;
        if (limit_switches[MC_MOTORID_R].max_point)
        {
            stepper_motors[MC_MOTORID_R].currPos = MC_MAXPOS_R;
            stepper_motors[MC_MOTORID_R].allowedDir = MC_ALLOWDIR_NEGDIR;
        }
        else
        {
            stepper_motors[MC_MOTORID_R].allowedDir = MC_ALLOWDIR_BOTHDIR;
        }
        break;
    case lsw_phi_null_Pin: // || lsw_z_null_Pin (These pins have the same number.)
        limit_switches[MC_MOTORID_PHI].null_point = HAL_GPIO_ReadPin(lsw_phi_null_GPIO_Port, lsw_phi_null_Pin) == LSW_PHI_NULL_ACTIVE;
        if (limit_switches[MC_MOTORID_PHI].null_point)
        {
            stepper_motors[MC_MOTORID_PHI].currPos = 0;
            stepper_motors[MC_MOTORID_PHI].allowedDir = MC_ALLOWDIR_POSDIR;
        }
        else
        {
            stepper_motors[MC_MOTORID_PHI].allowedDir = MC_ALLOWDIR_BOTHDIR;
        }
    case lsw_phi_max_Pin:
        limit_switches[MC_MOTORID_PHI].max_point = HAL_GPIO_ReadPin(lsw_phi_max_GPIO_Port, lsw_phi_max_Pin) == LSW_PHI_MAX_ACTIVE;
        if (limit_switches[MC_MOTORID_PHI].max_point)
        {
            stepper_motors[MC_MOTORID_PHI].currPos = MC_MAXPOS_PHI;
            stepper_motors[MC_MOTORID_PHI].allowedDir = MC_ALLOWDIR_NEGDIR;
        }
        else
        {
            stepper_motors[MC_MOTORID_PHI].allowedDir = MC_ALLOWDIR_BOTHDIR;
        }
        break;
    case lsw_z_null_Pin:
        limit_switches[MC_MOTORID_Z].null_point = HAL_GPIO_ReadPin(lsw_z_null_GPIO_Port, lsw_z_null_Pin) == LSW_Z_NULL_ACTIVE;
        if (limit_switches[MC_MOTORID_Z].null_point)
        {
            stepper_motors[MC_MOTORID_Z].currPos = 0;
            stepper_motors[MC_MOTORID_Z].allowedDir = MC_ALLOWDIR_POSDIR;
        }
        else
        {
            stepper_motors[MC_MOTORID_Z].allowedDir = MC_ALLOWDIR_BOTHDIR;
        }
        break;
    case lsw_z_max_Pin:
        limit_switches[MC_MOTORID_Z].max_point = HAL_GPIO_ReadPin(lsw_z_max_GPIO_Port, lsw_z_max_Pin) == LSW_Z_MAX_ACTIVE;
        if (limit_switches[MC_MOTORID_Z].max_point)
        {
            stepper_motors[MC_MOTORID_Z].currPos = MC_MAXPOS_Z;
            stepper_motors[MC_MOTORID_Z].allowedDir = MC_ALLOWDIR_NEGDIR;
        }
        else
        {
            stepper_motors[MC_MOTORID_Z].allowedDir = MC_ALLOWDIR_BOTHDIR;
        }
        break;
    }

    // If xHigherPriorityTaskWoken is now set to pdTRUE then a context switch should be requested.
    portYIELD_FROM_ISR(xHigherPriorityTaskWoken);
}

/*
 *===================================================================*
 * Function name: HAL_TIM_PWM_PulseFinishedCallback
 *-------------------------------------------------------------------
 * Description:
 * TIM1, TIM2 and TIM3 control the motors with PWM signals. Every rising edge of a PWM signal triggers a timer interrupt.
 * This handler increases or decreases the current position value of the appropriate motor depending on it's moving direction.
 * This way I don't need encoders to know where is the arm in the coordinate system.
 *
 * INPUT:
 * @param (TIM_HandleTypeDef*) htim: Timer handler which had triggered the interrupt.
 *
 * OUTPUT: none
 *-------------------------------------------------------------------
 */
void HAL_TIM_PWM_PulseFinishedCallback(TIM_HandleTypeDef *htim)
{
    if ((htim->Instance == stepper_motors[MC_MOTORID_R].TIM->Instance)
            && (stepper_motors[MC_MOTORID_R].motorState == MC_STATE_RUNNING))
    {
        if (MC_DIR_NEGATIVE == stepper_motors[MC_MOTORID_R].dir)
        {
            stepper_motors[MC_MOTORID_R].currPos--;
        }
        else if (MC_DIR_POSITIVE == stepper_motors[MC_MOTORID_R].dir)
        {
            stepper_motors[MC_MOTORID_R].currPos++;
        }
    }
    if ((htim->Instance == stepper_motors[MC_MOTORID_PHI].TIM->Instance)
            && (stepper_motors[MC_MOTORID_PHI].motorState == MC_STATE_RUNNING))
    {
        if (MC_DIR_NEGATIVE == stepper_motors[MC_MOTORID_PHI].dir)
        {
            stepper_motors[MC_MOTORID_PHI].currPos--;
        }
        else if (MC_DIR_POSITIVE == stepper_motors[MC_MOTORID_PHI].dir)
        {
            stepper_motors[MC_MOTORID_PHI].currPos++;
        }
    }
    if ((htim->Instance == stepper_motors[MC_MOTORID_Z].TIM->Instance)
            && (stepper_motors[MC_MOTORID_Z].motorState == MC_STATE_RUNNING))
    {
        if (MC_DIR_NEGATIVE == stepper_motors[MC_MOTORID_Z].dir)
        {
            stepper_motors[MC_MOTORID_Z].currPos--;
        }
        else if (MC_DIR_POSITIVE == stepper_motors[MC_MOTORID_Z].dir)
        {
            stepper_motors[MC_MOTORID_Z].currPos++;
        }
    }
}

void HAL_UART_RxCpltCallback(UART_HandleTypeDef *huart)
{
    BaseType_t xHigherPriorityTaskWoken = pdFALSE;

    if (huart->Instance == huart8.Instance)
    {
        WifiController_SerialHelper_UartRxCallbackFromISR(&xHigherPriorityTaskWoken);
    }

    portYIELD_FROM_ISR(xHigherPriorityTaskWoken);
}

/* USER CODE END Application */
